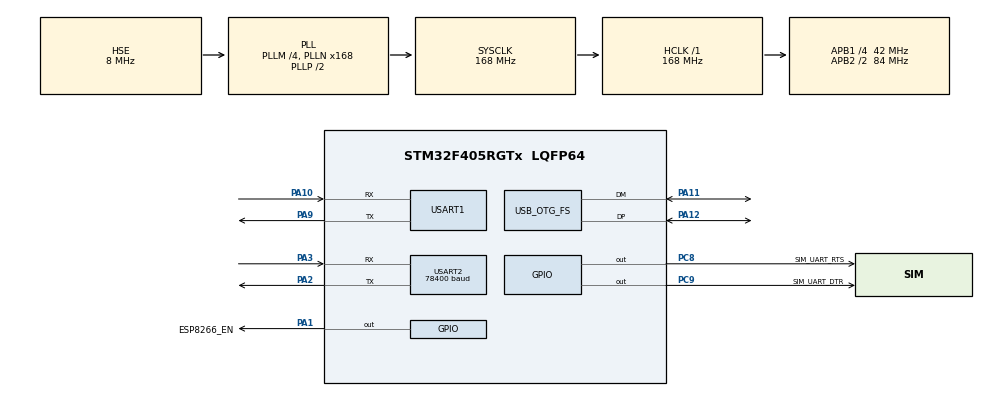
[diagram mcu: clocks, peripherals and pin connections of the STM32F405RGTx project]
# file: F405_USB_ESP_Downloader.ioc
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Dma.Request0=USART2_TX
Dma.Request1=USART2_RX
Dma.USART2_RX.1.Direction=DMA_PERIPH_TO_MEMORY
Dma.USART2_RX.1.FIFOMode=DMA_FIFOMODE_DISABLE
Dma.USART2_RX.1.Instance=DMA1_Stream5
Dma.USART2_RX.1.MemDataAlignment=DMA_MDATAALIGN_BYTE
Dma.USART2_RX.1.MemInc=DMA_MINC_ENABLE
Dma.USART2_RX.1.Mode=DMA_NORMAL
Dma.USART2_RX.1.PeriphDataAlignment=DMA_PDATAALIGN_BYTE
Dma.USART2_RX.1.PeriphInc=DMA_PINC_DISABLE
Dma.USART2_RX.1.Priority=DMA_PRIORITY_LOW
Dma.USART2_TX.0.Direction=DMA_MEMORY_TO_PERIPH
Dma.USART2_TX.0.FIFOMode=DMA_FIFOMODE_DISABLE
Dma.USART2_TX.0.Instance=DMA1_Stream6
Dma.USART2_TX.0.MemDataAlignment=DMA_MDATAALIGN_BYTE
Dma.USART2_TX.0.MemInc=DMA_MINC_ENABLE
Dma.USART2_TX.0.Mode=DMA_NORMAL
Dma.USART2_TX.0.PeriphDataAlignment=DMA_PDATAALIGN_BYTE
Dma.USART2_TX.0.PeriphInc=DMA_PINC_DISABLE
Dma.USART2_TX.0.Priority=DMA_PRIORITY_LOW
Mcu.Family=STM32F4
Mcu.Name=STM32F405RGTx
Mcu.Package=LQFP64
NVIC.DMA1_Stream5_IRQn=true\:0\:0\:false\:false\:true\:false\:true\:true
NVIC.DMA1_Stream6_IRQn=true\:0\:0\:false\:false\:true\:false\:true\:true
NVIC.OTG_FS_IRQn=true\:0\:0\:false\:false\:true\:false\:true\:true
NVIC.PriorityGroup=NVIC_PRIORITYGROUP_4
NVIC.USART2_IRQn=true\:0\:0\:false\:false\:true\:true\:true\:true
PA1.GPIO_Label=ESP8266_EN
PA1.Signal=GPIO_Output
PA10.Mode=Asynchronous
PA10.Signal=USART1_RX
PA11.Mode=Device_Only
PA11.Signal=USB_OTG_FS_DM
PA12.Mode=Device_Only
PA12.Signal=USB_OTG_FS_DP
PA13.Mode=Serial_Wire
PA13.Signal=SYS_JTMS-SWDIO
PA14.Mode=Serial_Wire
PA14.Signal=SYS_JTCK-SWCLK
PA2.Mode=Asynchronous
PA2.Signal=USART2_TX
PA3.Mode=Asynchronous
PA3.Signal=USART2_RX
PA9.Mode=Asynchronous
PA9.Signal=USART1_TX
PC8.GPIO_Label=SIM_UART_RTS
PC8.GPIO_Speed=GPIO_SPEED_FREQ_VERY_HIGH
PC8.Signal=GPIO_Output
PC9.GPIO_Label=SIM_UART_DTR
PC9.GPIO_Speed=GPIO_SPEED_FREQ_VERY_HIGH
PC9.Signal=GPIO_Output
PH0-OSC_IN.Mode=HSE-External-Oscillator
PH0-OSC_IN.Signal=RCC_OSC_IN
PH1-OSC_OUT.Mode=HSE-External-Oscillator
PH1-OSC_OUT.Signal=RCC_OSC_OUT
ProjectManager.HeapSize=0x200
ProjectManager.StackSize=0x400
ProjectManager.TargetToolchain=MDK-ARM V5.32
RCC.48MHZClocksFreq_Value=48000000
RCC.AHBFreq_Value=168000000
RCC.APB1CLKDivider=RCC_HCLK_DIV4
RCC.APB1Freq_Value=42000000
RCC.APB1TimFreq_Value=84000000
RCC.APB2CLKDivider=RCC_HCLK_DIV2
RCC.APB2Freq_Value=84000000
RCC.APB2TimFreq_Value=168000000
RCC.CortexFreq_Value=168000000
RCC.HCLKFreq_Value=168000000
RCC.HSE_VALUE=8000000
RCC.HSI_VALUE=16000000
RCC.LSE_VALUE=32768
RCC.PLLM=4
RCC.PLLN=168
RCC.PLLQ=7
RCC.SYSCLKFreq_VALUE=168000000
RCC.SYSCLKSource=RCC_SYSCLKSOURCE_PLLCLK
RCC.VCOOutputFreq_Value=336000000
USART1.VirtualMode=VM_ASYNC
USART2.BaudRate=78400
USART2.VirtualMode=VM_ASYNC
USB_DEVICE.CLASS_NAME_FS=CDC
USB_DEVICE.VirtualMode-CDC_FS=Cdc
USB_DEVICE.VirtualModeFS=Cdc_FS
USB_OTG_FS.VirtualMode=Device_Only
VP_USB_DEVICE_VS_USB_DEVICE_CDC_FS.Mode=CDC_FS
board=custom

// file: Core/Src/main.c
/* USER CODE BEGIN Header */
/**
  ******************************************************************************
  * @file           : main.c
  * @brief          : Main program body
  ******************************************************************************
  * @attention
  *
  * Copyright (c) 2025 STMicroelectronics.
  * All rights reserved.
  *
  * This software is licensed under terms that can be found in the LICENSE file
  * in the root directory of this software component.
  * If no LICENSE file comes with this software, it is provided AS-IS.
  *
  ******************************************************************************
  */
/* USER CODE END Header */
#include "main.h"
#include "dma.h"
#include "usart.h"
#include "usb_device.h"
#include "gpio.h"

/* USER CODE BEGIN Includes */
#include "Lime_USB_Uart.h"
#include "usbd_cdc_if.h"
/* USER CODE END Includes */

void SystemClock_Config(void);

/* USER CODE BEGIN 0 */
volatile uint8_t uart2RecvData = 0;
/* USER CODE END 0 */

int main(void)
{

  /* USER CODE BEGIN 1 */
	while(1)
		;
  /* USER CODE END 1 */

  /* MCU Configuration--------------------------------------------------------*/

  /* Reset of all peripherals, Initializes the Flash interface and the Systick. */
  HAL_Init();

  /* Configure the system clock */
  SystemClock_Config();

  /* Initialize all configured peripherals */
  MX_GPIO_Init();
  MX_DMA_Init();
  MX_USART2_UART_Init();
  MX_USB_DEVICE_Init();
  MX_USART1_UART_Init();
  /* USER CODE BEGIN 2 */
	printf("ESP Downloader Start!\n");
	printf("Compile Time:%s,%s\n", __DATE__, __TIME__);

	HAL_GPIO_WritePin(ESP8266_EN_GPIO_Port, ESP8266_EN_Pin, GPIO_PIN_SET);

	// UART2 DMA初始化
	UART2_DMA_Init();

	// 启动UART2 DMA接收
	UART2_Start_Receive();

	printf("USB转UART2模块启动完成\n");
	printf("UART2配置: 波特率%d, 数据位%d, 校验位%d, 停止位%d\n",
					 huart2.Init.BaudRate, huart2.Init.WordLength,
					 huart2.Init.Parity, huart2.Init.StopBits);

  /* USER CODE END 2 */

  /* Infinite loop */
  /* USER CODE BEGIN WHILE */
  while (1)
  {
//		CDC_Transmit_FS("HelloYQY USB\n", 13);
//
		HAL_Delay(1000);
    /* USER CODE END WHILE */

  }
}

void SystemClock_Config(void)
{
  RCC_OscInitTypeDef RCC_OscInitStruct = {0};
  RCC_ClkInitTypeDef RCC_ClkInitStruct = {0};

  /** Configure the main internal regulator output voltage
  */
  __HAL_RCC_PWR_CLK_ENABLE();
  __HAL_PWR_VOLTAGESCALING_CONFIG(PWR_REGULATOR_VOLTAGE_SCALE1);

  /** Initializes the RCC Oscillators according to the specified parameters
  * in the RCC_OscInitTypeDef structure.
  */
  RCC_OscInitStruct.OscillatorType = RCC_OSCILLATORTYPE_HSE;
  RCC_OscInitStruct.HSEState = RCC_HSE_ON;
  RCC_OscInitStruct.PLL.PLLState = RCC_PLL_ON;
  RCC_OscInitStruct.PLL.PLLSource = RCC_PLLSOURCE_HSE;
  RCC_OscInitStruct.PLL.PLLM = 4;
  RCC_OscInitStruct.PLL.PLLN = 168;
  RCC_OscInitStruct.PLL.PLLP = RCC_PLLP_DIV2;
  RCC_OscInitStruct.PLL.PLLQ = 7;
  if (HAL_RCC_OscConfig(&RCC_OscInitStruct) != HAL_OK)
  {
    Error_Handler();
  }

  /** Initializes the CPU, AHB and APB buses clocks
  */
  RCC_ClkInitStruct.ClockType = RCC_CLOCKTYPE_HCLK|RCC_CLOCKTYPE_SYSCLK
                              |RCC_CLOCKTYPE_PCLK1|RCC_CLOCKTYPE_PCLK2;
  RCC_ClkInitStruct.SYSCLKSource = RCC_SYSCLKSOURCE_PLLCLK;
  RCC_ClkInitStruct.AHBCLKDivider = RCC_SYSCLK_DIV1;
  RCC_ClkInitStruct.APB1CLKDivider = RCC_HCLK_DIV4;
  RCC_ClkInitStruct.APB2CLKDivider = RCC_HCLK_DIV2;

  if (HAL_RCC_ClockConfig(&RCC_ClkInitStruct, FLASH_LATENCY_5) != HAL_OK)
  {
    Error_Handler();
  }
}

void Error_Handler(void)
{
  __disable_irq();
  while (1)
  {
  }
}
